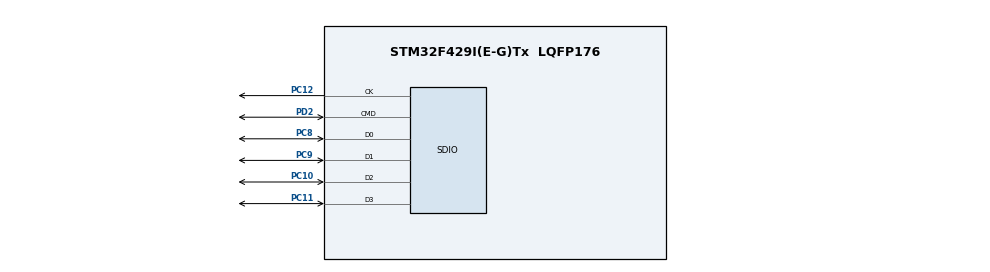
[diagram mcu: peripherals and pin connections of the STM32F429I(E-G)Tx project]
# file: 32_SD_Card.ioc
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Mcu.Family=STM32F4
Mcu.Name=STM32F429I(E-G)Tx
Mcu.Package=LQFP176
NVIC.PriorityGroup=NVIC_PRIORITYGROUP_4
PA13.Mode=Trace_Asynchronous_SW
PA13.Signal=SYS_JTMS-SWDIO
PA14.Mode=Trace_Asynchronous_SW
PA14.Signal=SYS_JTCK-SWCLK
PB3.Mode=Trace_Asynchronous_SW
PB3.Signal=SYS_JTDO-SWO
PC10.Mode=SD_4_bits_Wide_bus
PC10.Signal=SDIO_D2
PC11.Mode=SD_4_bits_Wide_bus
PC11.Signal=SDIO_D3
PC12.Mode=SD_4_bits_Wide_bus
PC12.Signal=SDIO_CK
PC14/OSC32_IN.Mode=LSE-External-Oscillator
PC14/OSC32_IN.Signal=RCC_OSC32_IN
PC15/OSC32_OUT.Mode=LSE-External-Oscillator
PC15/OSC32_OUT.Signal=RCC_OSC32_OUT
PC8.Mode=SD_4_bits_Wide_bus
PC8.Signal=SDIO_D0
PC9.Mode=SD_4_bits_Wide_bus
PC9.Signal=SDIO_D1
PD2.Mode=SD_4_bits_Wide_bus
PD2.Signal=SDIO_CMD
PH0/OSC_IN.Mode=HSE-External-Oscillator
PH0/OSC_IN.Signal=RCC_OSC_IN
PH1/OSC_OUT.Mode=HSE-External-Oscillator
PH1/OSC_OUT.Signal=RCC_OSC_OUT
ProjectManager.HeapSize=0x200
ProjectManager.StackSize=0x400
ProjectManager.TargetToolchain=STM32CubeIDE
RCC.48MHZClocksFreq_Value=45000000
RCC.AHBFreq_Value=180000000
RCC.APB1CLKDivider=RCC_HCLK_DIV4
RCC.APB1Freq_Value=45000000
RCC.APB1TimFreq_Value=90000000
RCC.APB2CLKDivider=RCC_HCLK_DIV2
RCC.APB2Freq_Value=90000000
RCC.APB2TimFreq_Value=180000000
RCC.CortexFreq_Value=180000000
RCC.HCLKFreq_Value=180000000
RCC.HSE_VALUE=25000000
RCC.HSI_VALUE=16000000
RCC.PLLM=15
RCC.PLLN=216
RCC.PLLQ=8
RCC.PLLSourceVirtual=RCC_PLLSOURCE_HSE
RCC.SYSCLKFreq_VALUE=180000000
RCC.SYSCLKSource=RCC_SYSCLKSOURCE_PLLCLK
RCC.VCOOutputFreq_Value=360000000
board=custom

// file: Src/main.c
/* USER CODE BEGIN Header */
/**
 ******************************************************************************
 * @file           : main.c
 * @brief          : Main program body
 ******************************************************************************
 * @attention
 *
 * <h2><center>&copy; Copyright (c) 2019 STMicroelectronics.
 * All rights reserved.</center></h2>
 *
 * This software component is licensed by ST under BSD 3-Clause license,
 * the "License"; You may not use this file except in compliance with the
 * License. You may obtain a copy of the License at:
 *                        opensource.org/licenses/BSD-3-Clause
 *
 ******************************************************************************
 */
/* USER CODE END Header */

#include "main.h"
#include "sdio.h"
#include "gpio.h"

/* USER CODE BEGIN Includes */
#include <stdio.h>
/* USER CODE END Includes */

/* USER CODE BEGIN PV */
extern SD_HandleTypeDef hsd;
/* USER CODE END PV */

void SystemClock_Config (void);

int main (void)
{

    /* MCU Configuration--------------------------------------------------------*/

    /* Reset of all peripherals, Initializes the Flash interface and the Systick. */
    HAL_Init ();

    /* Configure the system clock */
    SystemClock_Config ();

    /* Initialize all configured peripherals */
    MX_GPIO_Init ();
    MX_SDIO_SD_Init ();
    /* USER CODE BEGIN 2 */
    printf ("Start\r\n");
    //printf("Size %ld\r\n",hsd.SdCard.BlockSize * hsd.SdCard.BlockNbr);
    uint64_t t, t1;
    t = (uint64_t) hsd.SdCard.BlockSize * (uint64_t) hsd.SdCard.BlockNbr;
    t = t >> 20;
    printf ("Size %lu ,, %ld\r\n", t,t1);
    /* USER CODE END 2 */

    /* Infinite loop */
    while (1)
    {

    }
}

void SystemClock_Config (void)
{
    RCC_OscInitTypeDef RCC_OscInitStruct = { 0 };
    RCC_ClkInitTypeDef RCC_ClkInitStruct = { 0 };

    /** Configure the main internal regulator output voltage
     */
    __HAL_RCC_PWR_CLK_ENABLE();
    __HAL_PWR_VOLTAGESCALING_CONFIG(PWR_REGULATOR_VOLTAGE_SCALE1);
    /** Initializes the CPU, AHB and APB busses clocks
     */
    RCC_OscInitStruct.OscillatorType = RCC_OSCILLATORTYPE_HSE;
    RCC_OscInitStruct.HSEState = RCC_HSE_ON;
    RCC_OscInitStruct.PLL.PLLState = RCC_PLL_ON;
    RCC_OscInitStruct.PLL.PLLSource = RCC_PLLSOURCE_HSE;
    RCC_OscInitStruct.PLL.PLLM = 15;
    RCC_OscInitStruct.PLL.PLLN = 216;
    RCC_OscInitStruct.PLL.PLLP = RCC_PLLP_DIV2;
    RCC_OscInitStruct.PLL.PLLQ = 8;
    if (HAL_RCC_OscConfig (&RCC_OscInitStruct) != HAL_OK)
    {
	Error_Handler ();
    }
    /** Activate the Over-Drive mode
     */
    if (HAL_PWREx_EnableOverDrive () != HAL_OK)
    {
	Error_Handler ();
    }
    /** Initializes the CPU, AHB and APB busses clocks
     */
    RCC_ClkInitStruct.ClockType = RCC_CLOCKTYPE_HCLK | RCC_CLOCKTYPE_SYSCLK | RCC_CLOCKTYPE_PCLK1 | RCC_CLOCKTYPE_PCLK2;
    RCC_ClkInitStruct.SYSCLKSource = RCC_SYSCLKSOURCE_PLLCLK;
    RCC_ClkInitStruct.AHBCLKDivider = RCC_SYSCLK_DIV1;
    RCC_ClkInitStruct.APB1CLKDivider = RCC_HCLK_DIV4;
    RCC_ClkInitStruct.APB2CLKDivider = RCC_HCLK_DIV2;

    if (HAL_RCC_ClockConfig (&RCC_ClkInitStruct, FLASH_LATENCY_5) != HAL_OK)
    {
	Error_Handler ();
    }
}

/* USER CODE BEGIN 4 */

int _write (int file,char*ptr,int len)
{
    int DataIdx;
    for (DataIdx = 0; DataIdx < len; DataIdx++)
    {
	ITM_SendChar (*ptr++);
    }
    return len;
}

/* USER CODE END 4 */

void Error_Handler (void)
{
}

/************************ (C) COPYRIGHT STMicroelectronics *****END OF FILE****/
